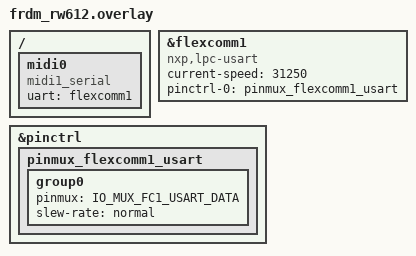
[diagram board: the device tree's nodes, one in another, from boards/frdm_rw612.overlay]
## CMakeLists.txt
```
# Zephyr MIDI1 Driver Loopback Test
# SPDX-License-Identifier: Apache-2.0

cmake_minimum_required(VERSION 3.20.0)

# Set the bindings path so devicetree can find our custom bindings
set(DTS_ROOT ${CMAKE_CURRENT_SOURCE_DIR}/../../)

find_package(Zephyr REQUIRED HINTS $ENV{ZEPHYR_BASE})
project(midi1_driver_test)

# We include the driver sources here to simplify for the test app
target_sources(app PRIVATE 
    src/main.c
    ../../drivers/midi1_serial.c
    ../../drivers/midi1.c
)

# Include the driver directory so we can find the headers
target_include_directories(app PRIVATE ${CMAKE_CURRENT_SOURCE_DIR}/../../drivers)
```

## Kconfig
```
source "Kconfig.zephyr"
rsource "../../drivers/Kconfig"
```

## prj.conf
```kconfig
CONFIG_ZTEST=y
CONFIG_ZTEST_STACK_SIZE=4096
CONFIG_UART_INTERRUPT_DRIVEN=y
CONFIG_MIDI1_SERIAL=y
CONFIG_RING_BUFFER=y
CONFIG_LOG=y
CONFIG_CBPRINTF_FP_SUPPORT=y
```

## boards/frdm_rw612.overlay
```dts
/**
 * Device tree overlay created for the FRDM_RW612 development kit
 * adjusted the pinmux so that we can use it for MIDI out and in.
 * @author Jan-Willem Smaal <usenet@gispen.org>
 * @date 20241223
 * updated in 20260206
 * license SPDX-License-Identifier: Apache-2.0
 */
 
/* 
 * Configured with the MIDI BAUD rate of 31250 
 * This is the USART on the MIDI arduino shield. 
 * GPIO 8 and 9. 
 */
&flexcomm1 {
	compatible = "nxp,lpc-usart";
	status = "okay";
	current-speed = <31250>;
	pinctrl-0 = <&pinmux_flexcomm1_usart>;
	pinctrl-names = "default";
};

/* 
 * We want to set flexcomm1 to USART instead of the default. 
 * this is why we need to set the pinmux here. 
 */
&pinctrl {
	pinmux_flexcomm1_usart: pinmux_flexcomm1_usart {
		group0 {
			pinmux = <IO_MUX_FC1_USART_DATA>;
			slew-rate = "normal";
		};
	};
};

/ {
	/* MIDI1.0 serial USART driver, set the uart baud to 31250. */
	midi0: midi0 {
		status = "okay";
		compatible = "midi1_serial";
		uart = <&flexcomm1>;
	};
};

/* EOF */
```

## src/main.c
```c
#include <zephyr/ztest.h>
#include <zephyr/device.h>
#include <zephyr/drivers/uart.h>
#include <zephyr/kernel.h>
#include <midi1_serial.h>

#define MIDI_DEV DT_NODELABEL(midi0)
static const struct device *midi_dev = DEVICE_DT_GET(MIDI_DEV);

ZTEST_USER(midi_driver_tests, test_baseline)
{
	zassert_true(device_is_ready(midi_dev), "MIDI device not ready");
}

static void *midi_driver_tests_setup(void)
{
	return NULL;
}

ZTEST_SUITE(midi_driver_tests, NULL, midi_driver_tests_setup, NULL, NULL, NULL);
```
